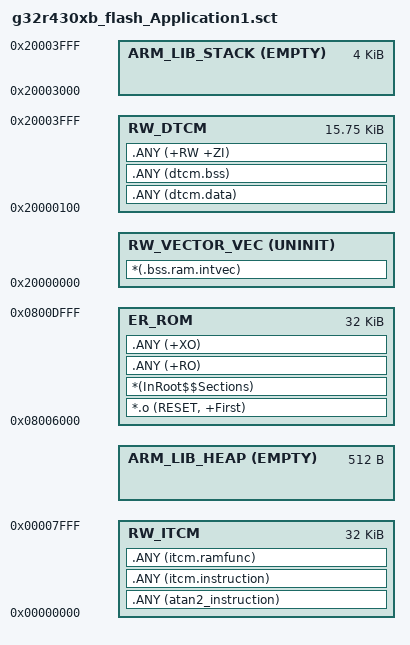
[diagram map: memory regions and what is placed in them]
#! armclang -E --target=arm-arm-none-eabi -mcpu=cortex-m52 -xc
; command above MUST be in first line (no comment above!)

/*
;-------- <<< Use Configuration Wizard in Context Menu >>> -------------------
*/

/*--------------------- Flash Configuration ----------------------------------
; <h> Flash Configuration
;   <o0> Flash Base Address <0x0-0xFFFFFFFF:8>
;   <o1> Flash Size (in Bytes) <0x0-0xFFFFFFFF:8>
; </h>
----------------------------------------------------------------------------*/
#define __ROM_BASE      0x08006000
#define __ROM_SIZE      0x00008000

/*--------------------- Embedded RAM Configuration ---------------------------
; <h> ITCM Configuration
;   <o0> ITCM Base Address    <0x0-0xFFFFFFFF:8>
;   <o1> ITCM Size (in Bytes) <0x0-0xFFFFFFFF:8>
; </h>

; <h> DTCM Configuration
;   <o3> DTCM Base Address    <0x0-0xFFFFFFFF:8>
;   <o4> DTCM Size (in Bytes) <0x0-0xFFFFFFFF:8>
; </h>
----------------------------------------------------------------------------*/
#define __ITCM_BASE     0x00000000
#define __ITCM_SIZE     0x00008000  /* 32KB ITCM */

#define __DTCM_BASE     0x20000000
#define __DTCM_SIZE     0x00004000  /* 16KB DTCM */

/*--------------------- Stack / Heap Configuration ---------------------------
; <h> Stack / Heap Configuration
;   <o0> Stack Size (in Bytes) <0x0-0xFFFFFFFF:8>
;   <o1> Heap Size (in Bytes) <0x0-0xFFFFFFFF:8>
; </h>
----------------------------------------------------------------------------*/
#define __STACK_SIZE    0x00001000
#define __HEAP_SIZE     0x00000200

/*--------------------- Vector Configuration ---------------------------
; <h> Vector Execution Region Configuration
;   <o> Vector Execution Region
;      <0=> DTCM (Default)
;      <1=> ITCM
;      <2=> Flash
; </h>
 *----------------------------------------------------------------------------*/
#define __VECTOR_REGION  0

/*--------------------- atan2 lib Configuration ---------------------------
; <h> atan2 Code Execution Region Configuration
;   <o> atan2 Code Execution Region
;      <0=> ITCM (Default)
;      <1=> Flash
; </h>
 *----------------------------------------------------------------------------*/
#define __CODE_ATAN2_REGION  0

/*
;------------- <<< end of configuration section >>> ---------------------------
*/
#define __VECTOR_SIZE   0x00000100

#if __VECTOR_REGION == 0
#define __VECTOR_BASE   __DTCM_BASE
#define __DTCM_RW_BASE  (__DTCM_BASE + __VECTOR_SIZE)
#define __DTCM_RW_SIZE  (__DTCM_SIZE - __VECTOR_SIZE)

#define __ITCM_RW_BASE  __ITCM_BASE
#define __ITCM_RW_SIZE  __ITCM_SIZE

#elif __VECTOR_REGION == 1
#define __VECTOR_BASE    __ITCM_BASE
#define __DTCM_RW_BASE   __DTCM_BASE
#define __DTCM_RW_SIZE   __DTCM_SIZE

#define __ITCM_RW_BASE  (__ITCM_BASE + __VECTOR_SIZE)
#define __ITCM_RW_SIZE  (__ITCM_SIZE - __VECTOR_SIZE)

#elif __VECTOR_REGION == 2
#define __DTCM_RW_BASE   __DTCM_BASE
#define __DTCM_RW_SIZE   __DTCM_SIZE

#define __ITCM_RW_BASE  __ITCM_BASE
#define __ITCM_RW_SIZE  __ITCM_SIZE
#endif


/*----------------------------------------------------------------------------
Stack & Heap
----------------------------------------------------------------------------*/
#define __STACK_TOP     (__DTCM_BASE + __DTCM_SIZE)
#define __HEAP_BASE     (AlignExpr(+0, 8))

#define __RO_BASE       __ROM_BASE
#define __RO_SIZE       __ROM_SIZE


LR_ROM __RO_BASE __RO_SIZE
{
    ER_ROM __RO_BASE __RO_SIZE
    {
        *.o (RESET, +First)
        *(InRoot$$Sections)
        .ANY (+RO)
        .ANY (+XO)
#if __CODE_ATAN2_REGION == 1
       .ANY (atan2_instruction)
#endif
    }

    RW_DTCM __DTCM_RW_BASE __DTCM_RW_SIZE
    {
        .ANY (dtcm.data)
        .ANY (dtcm.bss)
        .ANY (+RW +ZI)
    }

    RW_ITCM __ITCM_RW_BASE __ITCM_RW_SIZE
    {
#if __CODE_ATAN2_REGION == 0
        .ANY (atan2_instruction)
#endif
        .ANY (itcm.instruction)
        .ANY (itcm.ramfunc)
        
    }

#if __HEAP_SIZE > 0
    ARM_LIB_HEAP __HEAP_BASE EMPTY __HEAP_SIZE
    {
    ; Reserve empty region for heap
    }
#endif

    ARM_LIB_STACK __STACK_TOP EMPTY -__STACK_SIZE
    {
        ; Reserve empty region for stack
    }
}

#if __VECTOR_REGION != 2
LR_ROM2 __VECTOR_BASE
{
    RW_VECTOR_VEC __VECTOR_BASE UNINIT
    {
          *(.bss.ram.intvec)
    }
}
#endif
